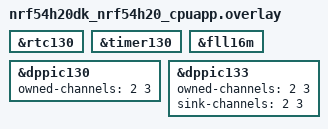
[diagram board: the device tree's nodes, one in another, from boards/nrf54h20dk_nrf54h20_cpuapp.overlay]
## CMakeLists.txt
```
cmake_minimum_required(VERSION 3.20.0)
find_package(Zephyr REQUIRED HINTS $ENV{ZEPHYR_BASE})

project(lfclk_probe)

target_sources(app PRIVATE src/main.c)
```

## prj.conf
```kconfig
CONFIG_LOG=y
CONFIG_LOG_MODE_DEFERRED=y
# Deferred because the software-gated measurement variant puts log calls in gate window.

# rtc130 and timer130 are read through the counter API. Both nrfx counter
# drivers are def_bool y on their DT_HAS_* symbol
# (zephyr/drivers/counter/Kconfig.nrfx), so enabling the nodes in the board
# overlay is enough and only the subsystem has to be asked for here.
CONFIG_COUNTER=y

# Gates every nrf clock driver: they all sit under "if CLOCK_CONTROL" in
# zephyr/drivers/clock_control/Kconfig. CLOCK_CONTROL_NRF_FLL16M is then
# default y on the DT node and pulls in CLOCK_CONTROL_NRF2_COMMON, which is
# where nrf_clock_control_request_sync() lives.
CONFIG_CLOCK_CONTROL=y
```

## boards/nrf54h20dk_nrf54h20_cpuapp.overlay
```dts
/*
 * Copyright (c) 2026 Nordic Semiconductor ASA
 *
 * SPDX-License-Identifier: Apache-2.0
 */

/*
 * Both nodes ship disabled in nrf54h20.dtsi and nothing on this board target
 * claims either one. Enabling them here instead of alongside the probe logic
 * keeps a resource conflict bisectable to this file.
 *
 * cpuapp has no core-local TIMER, RTC or DPPIC at all: nrf54h20_cpuapp.dtsi
 * deletes cpurad_peripherals, and cpuapp_peripherals holds only the local
 * HSFLL, IPCT, two WDTs, resetinfo and the 802.15.4 node. Everything below is
 * therefore in the global domain at peripheral@5f000000.
 */

/*
 * LF side of the measurement. rtc130 counts lfclk directly
 * (nrf54h20.dtsi rtc@928000: clocks = <&lfclk>, clock-frequency = <32768>,
 * prescaler = <1>, cc-num = <4>), which is the whole point: it is the only
 * counter here whose rate is the thing under test.
 */
&rtc130 {
	status = "okay";
};

/*
 * HF side. timer130 is clocked from fll16m with prescaler 0
 * (nrf54h20.dtsi timer@9a2000: clocks = <&fll16m>, prescaler = <0>,
 * cc-num = <6>, max-bit-width = <32>), so the reference is the 16 MHz slow
 * peripheral clock rather than anything DVFS touches.
 *
 * Not timer120 or timer121: those hang off hsfll120, which scales with DVFS,
 * and their IRQs are routed to FLPR by default. Not timer020/021/022 either,
 * those are cpurad-local and deleted from this build.
 */
&timer130 {
	status = "okay";
};

/*
 * timer130's clock parent, needed as a device and not just as a DT phandle so
 * accuracy can be requested on it before the gate. Disabled in nrf54h20.dtsi;
 * zephyr/tests/drivers/clock_control/nrf_clock_control has the same one-liner
 * in its cpuapp overlay.
 */
&fll16m {
	status = "okay";
};

/*
 * DPPI route for the hardware-gated variant. rtc130 sits on the 0x5f92_0000 bus
 * (SPU131) and timer130 on 0x5f9a_0000 (SPU134), confirmed by the generated
 * SPU_PERIPH_PERM entries, so an RTC event reaching a TIMER task has to cross a
 * PPIB bridge. dppic130 is the hub and takes no link property of its own; the
 * leaf declares the route and the periphconf generator emits both halves.
 *
 * One sink-channels entry on dppic133 produces, per
 * build/lfclk_probe/zephyr/periphconf_entries_generated.c:
 *   PERIPHCONF_PPIB_SUBSCRIBE_SEND(ppib130, 16, true)   PPIB130 ch. 16 =>
 *   PERIPHCONF_PPIB_PUBLISH_RECEIVE(ppib134, 0, true)   PPIB134 ch. 0
 * which matches offset = <16> on the ppib134 node.
 *
 * Do not give the ppib nodes a status. PPIBs are secure domain owned, and
 * claiming them emits SPU_PERIPH_PERM writes that periphconf-check rejects as
 * UNRECOGNIZED_REGISTER, which stops the device booting.
 *
 * MPSL reserves DPPIC130 channel 0 for itself
 * (MPSL_RESERVED_DPPI_SINK_CHANNELS in nrf/subsys/mpsl/init/mpsl_init.c), and
 * this probe is meant to coexist with a radio application. The first channel is
 * the start boundary, the second the end boundary, read back in C from these
 * properties so the numbers live in one place.
 *
 * The channel index is the same on both sides of the bridge. MPSL relies on the
 * same thing, enabling matching indices on DPPIC130 and DPPIC132 in
 * mpsl_init.c. The secure domain no longer enables local-domain DPPI channels,
 * so the application has to enable both sides itself.
 */
&dppic130 {
	status = "okay";
	owned-channels = <2 3>;
};

&dppic133 {
	status = "okay";
	owned-channels = <2 3>;
	sink-channels = <2 3>;
};
```

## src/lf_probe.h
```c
/*
 * Copyright (c) 2026 Nordic Semiconductor ASA
 *
 * SPDX-License-Identifier: Apache-2.0
 */

/**
 * @file
 * @brief Tunables for the LFCLK health probe, each with its origin.
 *
 * Anything a reviewer would otherwise have to derive lives here rather than
 * inline at the point of use.
 */

#ifndef LF_PROBE_H_
#define LF_PROBE_H_

#include <zephyr/devicetree.h>

/* What every measurement is compared against, straight from the lfclk node so
 * a board that declares something else does not need a code change.
 */
#define LF_NOMINAL_HZ DT_PROP(DT_NODELABEL(lfclk), clock_frequency)

/* Gate lengths in LF ticks. Multiples of 32 make the expected HF count integral:
 * 16e6 / 32768 = 488.28125, and 488.28125 * 32 = 15625.
 *
 * That only holds for the captured gate, where the window is exactly gate_ticks
 * wide. The software gate derives its expected count from the observed tick
 * delta, which overshoots, so its division truncates by up to one HF tick. That
 * is 0.06 ppm on the long gate. The verdict trusts the captured gate for that
 * reason. main.c asserts the multiples at build time.
 */
#define LF_GATE_TICKS_LONG   32768 /* 1 s, expected 16000000 HF ticks exactly */
#define LF_GATE_TICKS_SHORT  4096  /* 125 ms, expected 2000000 HF ticks exactly */
#define LF_GATE_TICKS_JITTER 32    /* ~1 ms, expected 15625 HF ticks exactly */

/* Gates per spread run. One 32 tick gate resolves only to 1 part in 15625, or
 * 64 ppm, so the spread figure comes from the summed deviation across all
 * samples rather than from any single gate. 64 samples takes the aggregate
 * resolution to about 1 ppm.
 */
#define LF_JITTER_SAMPLES 64

/* Margin allowed on top of a gate's own expected duration before the gate is
 * called dead. A gate that never closes means LFCLK is not advancing, which is
 * an outcome rather than an error.
 */
#define LF_CAPTURE_TIMEOUT_MS 2000

/* Above this, the LF source is not a crystal. Deliberately loose: lfclk
 * declares lflprc-accuracy-ppm at exactly 1000, so any threshold at or below
 * that sits on top of a legal mode. An uncalibrated LFRC is off by percent, so
 * 2000 keeps two decades of margin either side. It does not catch a calibrated
 * LFRC sitting near nominal, which is what the spread check is for.
 */
#define LF_PPM_REJECT 2000

/* Two-sided, measured on one DK at room temperature with the spread taken
 * inside the probe, straight after the 1 s gate, so the reference is already
 * settled.
 *
 *   crystal   mad 19 to  58 ppm    8 boots
 *   LFRC      mad 248 to 622 ppm   5 boots
 *
 * 150 sits 2.6x above the worst crystal reading and 1.65x below the quietest RC
 * one. The bias toward not raising false alarms is deliberate, because a bad
 * reading here latches the fault flag.
 *
 * Measure it inside the probe, not on its own. An earlier version ran the spread
 * from a fresh lf_ref_acquire() and read 76 to 110 ppm on the same crystal,
 * because it was measuring the HFXO ramp as well as the LF source.
 *
 * The RC side came from a BICR edit declaring source LFRC, which is the only way
 * to get a non-crystal LFCLK on this part. A runtime request is subsumed by SCFW
 * arbitration. See the README.
 *
 * TODO: re-check over temperature and on more than one board. Both figures come
 * from a single DK, and the crystal side threw one 58 ppm boot against a 19 to
 * 29 ppm cluster.
 */
#define LF_PPM_SPREAD_REJECT 150

/* The board's declared LFXO startup budget, from lfosc.lfxo.startupTimeMs in
 * zephyr/boards/nordic/nrf54h20dk/bicr.json. A probe at this point separates
 * dead from slow-starting, because the two differ only in time.
 *
 * The handoff attributed this to nrf_clock_control_get_startup_time(), which
 * would presumably report the same number, but this code never calls it: lfclk
 * is disabled in this build and only fll16m is queried. Enable &lfclk and ask if
 * you want that confirmed rather than inferred.
 */
#define LF_PROBE_EARLY_MS 600

/* Clears the LFXO calibration window. Calibration takes roughly 3.5 to 4 s
 * after a BICR write and timing is not accurate until it finishes, so probing
 * before this condemns good hardware intermittently.
 */
#define LF_PROBE_LATE_MS 5000

/* Hourly re-probe. A poll rather than a callback because nothing re-evaluates a
 * satisfied clock request: a crystal that dies at month six leaves every
 * clock_control API returning its day-one value.
 */
#define LF_MONITOR_PERIOD_MS 3600000

/* Consecutive good readings needed to clear a latched fault. A single good gate
 * after a bad one is as likely to be a marginal crystal drifting back through
 * tolerance as a real recovery, and clearing on it would hide the fault from
 * anything polling less often than the probe.
 */
#define LF_FAULT_CLEAR_STREAK 2

/* The monitor gets its own thread because a gate can busy-wait for a second,
 * which has no business on the system work queue. Low priority and preemptible:
 * the captured gate does not care about being preempted, since both boundaries
 * are taken in hardware.
 */
#define LF_MONITOR_STACK_SIZE 1024
#define LF_MONITOR_PRIO       K_PRIO_PREEMPT(10)

/* Lead time between arming the two compare values and the first one firing.
 * One LF tick is 30.5 us, so four is roughly 122 us, comfortably more than two
 * CC register writes even if something preempts between them. Too small and the
 * start boundary is already in the past and never fires.
 */
#define LF_CAPTURE_ARM_TICKS 4

/* DPPI channels for the captured gate, read back from the overlay so the
 * numbers are declared once. The first opens the window, the second closes it.
 */
#define LF_DPPI_CH_START DT_PROP_BY_IDX(DT_NODELABEL(dppic133), sink_channels, 0)
#define LF_DPPI_CH_END   DT_PROP_BY_IDX(DT_NODELABEL(dppic133), sink_channels, 1)

/* rtc130 CC channels publishing the two boundaries, and the timer130 CC
 * channels capturing them. Both peripherals are also bound to Zephyr counter
 * devices, which hand these same channels out for alarms, so the probe sets no
 * alarms and owns these outright. rtc130 has cc-num = 4 and timer130 cc-num = 6,
 * so nothing else is squeezed out.
 */
#define LF_RTC_CC_START   0
#define LF_RTC_CC_END     1
#define LF_TIMER_CC_START 0
#define LF_TIMER_CC_END   1

/** @brief Cycle-to-cycle spread across one run of short gates. */
struct lf_spread {
	/** Gates that completed. */
	uint32_t samples;
	/** Mean HF count across the run. */
	uint32_t hf_mean;
	/** Mean absolute deviation in HF ticks, truncated. */
	uint32_t hf_mad;
	/** Largest minus smallest HF count. */
	uint32_t hf_range;
	/** Deviation against the expected count, in ppm. */
	uint32_t mad_ppm;
	/** Range against the expected count, in ppm. */
	uint32_t range_ppm;
};

/** @brief What the probe concluded about LFCLK. */
enum lf_verdict {
	/** Ratio within tolerance. A crystal is present and running. */
	LF_OK,
	/** Ratio off by more than LF_PPM_REJECT. Running on an RC source. */
	LF_WRONG_SRC,
	/** Gate never completed. LFCLK is not advancing at all. */
	LF_ABSENT,
};

#endif /* LF_PROBE_H_ */
```
